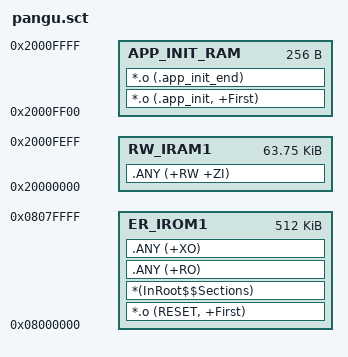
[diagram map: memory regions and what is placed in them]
; *************************************************************
; *** Scatter-Loading Description File generated by uVision ***
; *************************************************************

LR_IROM1 0x08000000 0x00080000  {    ; load region size_region
  ER_IROM1 0x08000000 0x00080000  {  ; load address = execution address
   *.o (RESET, +First)
   *(InRoot$$Sections)
   .ANY (+RO)
   .ANY (+XO)
  }
  RW_IRAM1 0x20000000 0x0000FF00  {  ; RW data
   ;*.o (.app_init)
   .ANY (+RW +ZI)
  }

  APP_INIT_RAM 0x2000FF00 0x100 { ; 如果空间较小，而实际用的比较多，会报size exceeds limit
   *.o (.app_init, +First)
   *.o (.app_init_end)
  }
}

